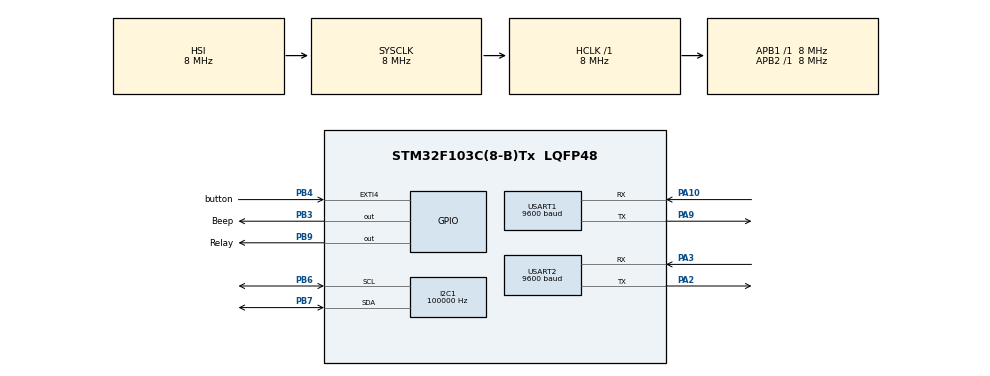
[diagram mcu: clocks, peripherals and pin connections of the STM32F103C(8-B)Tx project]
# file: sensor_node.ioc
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Mcu.Family=STM32F1
NVIC.EXTI4_IRQn=true\:0\:0\:false\:false\:true\:true\:true
PB9.GPIO_Label=Relay
PA10.Mode=Asynchronous
USART1.BaudRate=9600
USART2.BaudRate=9600
ProjectManager.StackSize=0x400
PA13.Signal=SYS_JTMS-SWDIO
PA3.Mode=Asynchronous
PA9.Mode=Asynchronous
I2C1.ClockSpeed=100000
ProjectManager.TargetToolchain=MDK-ARM V5.27
RCC.HCLKFreq_Value=8000000
RCC.APB2TimFreq_Value=8000000
PA9.Signal=USART1_TX
PB6.Signal=I2C1_SCL
PB6.Mode=I2C
RCC.USBFreq_Value=8000000
RCC.AHBFreq_Value=8000000
board=custom
RCC.APB2Freq_Value=8000000
PB4.GPIO_Label=button
PA14.Mode=Serial_Wire
PB7.Signal=I2C1_SDA
PA13.Mode=Serial_Wire
Mcu.Name=STM32F103C(8-B)Tx
PA2.Signal=USART2_TX
PB3.Signal=GPIO_Output
RCC.SYSCLKFreq_VALUE=8000000
Mcu.Package=LQFP48
PB9.Signal=GPIO_Output
USART2.VirtualMode=VM_ASYNC
USART1.VirtualMode=VM_ASYNC
PB7.Mode=I2C
PA10.Signal=USART1_RX
PA14.Signal=SYS_JTCK-SWCLK
ProjectManager.HeapSize=0x200
NVIC.PriorityGroup=NVIC_PRIORITYGROUP_4
RCC.APB1TimFreq_Value=8000000
PA2.Mode=Asynchronous
RCC.APB1Freq_Value=8000000
PB4.Signal=GPXTI4
PA3.Signal=USART2_RX
PB3.GPIO_Label=Beep

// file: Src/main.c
/* USER CODE BEGIN Header */
/**
  ******************************************************************************
  * @file           : main.c
  * @brief          : Main program body
  ******************************************************************************
  * @attention
  *
  * <h2><center>&copy; Copyright (c) 2020 STMicroelectronics.
  * All rights reserved.</center></h2>
  *
  * This software component is licensed by ST under BSD 3-Clause license,
  * the "License"; You may not use this file except in compliance with the
  * License. You may obtain a copy of the License at:
  *                        opensource.org/licenses/BSD-3-Clause
  *
  ******************************************************************************
  */
/* USER CODE END Header */

#include "main.h"
#include "stdio.h"
#include "i2c-lcd.h"

I2C_HandleTypeDef hi2c1;

UART_HandleTypeDef huart1;
UART_HandleTypeDef huart2;

void SystemClock_Config(void);
static void MX_GPIO_Init(void);
static void MX_I2C1_Init(void);
static void MX_USART1_UART_Init(void);
static void MX_USART2_UART_Init(void);
/* USER CODE BEGIN PFP */
int read_MHZ19(void);
void read_HDC(void);
void display(void);
float temp, humi;
unsigned char buffer[5];
unsigned char rawT, rawH;
int co2;

/* USER CODE END PFP */

int main(void)
{

  /* MCU Configuration--------------------------------------------------------*/

  /* Reset of all peripherals, Initializes the Flash interface and the Systick. */
  HAL_Init();

  /* Configure the system clock */
  SystemClock_Config();

  /* Initialize all configured peripherals */
  MX_GPIO_Init();
  MX_I2C1_Init();
  MX_USART1_UART_Init();
  MX_USART2_UART_Init();
buffer[0] = 0x02;
	buffer[1] = 0;
	buffer[2] = 0;
	HAL_I2C_Master_Transmit(&hi2c1, 0x40<<1, buffer, 3, 1000);
	//LCD setup
	lcd_init();
	lcd_goto_XY(1,0);
	lcd_send_string("T:");
	lcd_goto_XY(2,0);
	lcd_send_string("H:");
	lcd_goto_XY(1,7);
	lcd_send_string("CO2:");
	lcd_goto_XY(2,7);
	lcd_send_string("RELAY:");
	lcd_goto_XY(2,13);
	lcd_send_string("OFF");

  /* Infinite loop */
  while (1)
  {
		//display MHZ
		display();
		unsigned char send[4];
		send[0] = 0x42;
		send[1] = co2 >> 8;
		send[2] = co2;
		if(HAL_GPIO_ReadPin(Relay_GPIO_Port, Relay_Pin))	send[3] = 0x01;
		else send[3] = 0x00;
		HAL_UART_Transmit(&huart1, (uint8_t *)send, 4, 1000);
		HAL_Delay(2000);

  }
}
void display(void){
	lcd_goto_XY(1,0);
	lcd_send_string("T:");
	lcd_goto_XY(2,0);
	lcd_send_string("H:");
	lcd_goto_XY(1,7);
	lcd_send_string("CO2:");
	lcd_goto_XY(2,7);
	lcd_send_string("RELAY:");
	co2 = read_MHZ19();
		char tv_co2[4];
		sprintf(tv_co2,"%d",co2);
		lcd_goto_XY(1,12);
		lcd_send_string(tv_co2);
		//display HDC
		read_HDC();
		char tv_temp[5];
		char tv_humi[5];
		sprintf(tv_temp,"%2.f",temp);
		sprintf(tv_humi,"%2.f",humi);
		lcd_goto_XY(1,3);
		lcd_send_string(tv_temp);
		lcd_goto_XY(2,3);
		lcd_send_string(tv_humi);
}

int read_MHZ19(void){
	unsigned char cmd[9] = {0xFF, 0x01, 0x86, 0x00, 0x00, 0x00, 0x00, 0x00, 0x79};
  // command to ask for data
  unsigned char response[9]; // for answer
  HAL_UART_Transmit(&huart2,cmd,9,9600);
	if(HAL_UART_Receive(&huart2,response,9,2000)==HAL_OK){
		if (response[1] != 0x86){
			//Serial.println("Invalid response from co2 sensor!");
			return -1;
		}
		unsigned char crc = 0;
		for (int i = 1; i < 8; i++) {
			crc += response[i];
		}
		crc = 255 - crc + 1;
		if (response[8] == crc) {
			int responseHigh = (int) response[2];
			int responseLow = (int) response[3];
			int ppm = (256 * responseHigh) + responseLow;
			if(ppm <400) ppm = 400;
			else if(ppm>5000) ppm = 5000;
			else ppm = ppm;
			return ppm;
		} else {
			//Serial.println("CRC error!");
			return -1;
		}
	}
}

void read_HDC(void){
	//read temp
	buffer[0] = 0x00;
	HAL_I2C_Master_Transmit(&hi2c1, 0x40<<1, buffer,1,100);
	HAL_Delay(20);
	HAL_I2C_Master_Receive(&hi2c1, 0x40<<1, buffer,2,100);
	rawT = buffer[0] <<8|buffer[1];
	temp = (float)((rawT/65536)*165.0 -40);
	//reaq humi
	buffer[0] = 0x01;
	HAL_I2C_Master_Transmit(&hi2c1, 0x40<<1, buffer,1,1000);
	HAL_Delay(20);
	HAL_I2C_Master_Receive(&hi2c1, 0x40<<1, buffer,2,1000);
	rawH = buffer[0] <<8|buffer[1];
	humi = (float)((rawT/65536)*1000);
	//check data read
	if((temp<-20) || (temp>120)) temp = -1;
	else temp = temp;

	if((humi>99.99) || (humi<0.1)) humi = -1;
	else humi = humi;

}

void SystemClock_Config(void)
{
  RCC_OscInitTypeDef RCC_OscInitStruct = {0};
  RCC_ClkInitTypeDef RCC_ClkInitStruct = {0};

  /** Initializes the CPU, AHB and APB busses clocks
  */
  RCC_OscInitStruct.OscillatorType = RCC_OSCILLATORTYPE_HSI;
  RCC_OscInitStruct.HSIState = RCC_HSI_ON;
  RCC_OscInitStruct.HSICalibrationValue = RCC_HSICALIBRATION_DEFAULT;
  RCC_OscInitStruct.PLL.PLLState = RCC_PLL_NONE;
  if (HAL_RCC_OscConfig(&RCC_OscInitStruct) != HAL_OK)
  {
    Error_Handler();
  }
  /** Initializes the CPU, AHB and APB busses clocks
  */
  RCC_ClkInitStruct.ClockType = RCC_CLOCKTYPE_HCLK|RCC_CLOCKTYPE_SYSCLK
                              |RCC_CLOCKTYPE_PCLK1|RCC_CLOCKTYPE_PCLK2;
  RCC_ClkInitStruct.SYSCLKSource = RCC_SYSCLKSOURCE_HSI;
  RCC_ClkInitStruct.AHBCLKDivider = RCC_SYSCLK_DIV1;
  RCC_ClkInitStruct.APB1CLKDivider = RCC_HCLK_DIV1;
  RCC_ClkInitStruct.APB2CLKDivider = RCC_HCLK_DIV1;

  if (HAL_RCC_ClockConfig(&RCC_ClkInitStruct, FLASH_LATENCY_0) != HAL_OK)
  {
    Error_Handler();
  }
}

static void MX_I2C1_Init(void)
{

  hi2c1.Instance = I2C1;
  hi2c1.Init.ClockSpeed = 100000;
  hi2c1.Init.DutyCycle = I2C_DUTYCYCLE_2;
  hi2c1.Init.OwnAddress1 = 0;
  hi2c1.Init.AddressingMode = I2C_ADDRESSINGMODE_7BIT;
  hi2c1.Init.DualAddressMode = I2C_DUALADDRESS_DISABLE;
  hi2c1.Init.OwnAddress2 = 0;
  hi2c1.Init.GeneralCallMode = I2C_GENERALCALL_DISABLE;
  hi2c1.Init.NoStretchMode = I2C_NOSTRETCH_DISABLE;
  if (HAL_I2C_Init(&hi2c1) != HAL_OK)
  {
    Error_Handler();
  }

}

static void MX_USART1_UART_Init(void)
{

  huart1.Instance = USART1;
  huart1.Init.BaudRate = 9600;
  huart1.Init.WordLength = UART_WORDLENGTH_8B;
  huart1.Init.StopBits = UART_STOPBITS_1;
  huart1.Init.Parity = UART_PARITY_NONE;
  huart1.Init.Mode = UART_MODE_TX_RX;
  huart1.Init.HwFlowCtl = UART_HWCONTROL_NONE;
  huart1.Init.OverSampling = UART_OVERSAMPLING_16;
  if (HAL_UART_Init(&huart1) != HAL_OK)
  {
    Error_Handler();
  }

}

static void MX_USART2_UART_Init(void)
{

  huart2.Instance = USART2;
  huart2.Init.BaudRate = 9600;
  huart2.Init.WordLength = UART_WORDLENGTH_8B;
  huart2.Init.StopBits = UART_STOPBITS_1;
  huart2.Init.Parity = UART_PARITY_NONE;
  huart2.Init.Mode = UART_MODE_TX_RX;
  huart2.Init.HwFlowCtl = UART_HWCONTROL_NONE;
  huart2.Init.OverSampling = UART_OVERSAMPLING_16;
  if (HAL_UART_Init(&huart2) != HAL_OK)
  {
    Error_Handler();
  }

}

static void MX_GPIO_Init(void)
{
  GPIO_InitTypeDef GPIO_InitStruct = {0};

  /* GPIO Ports Clock Enable */
  __HAL_RCC_GPIOA_CLK_ENABLE();
  __HAL_RCC_GPIOB_CLK_ENABLE();

  /*Configure GPIO pin Output Level */
  HAL_GPIO_WritePin(GPIOB, Beep_Pin|Relay_Pin, GPIO_PIN_RESET);

  /*Configure GPIO pins : Beep_Pin Relay_Pin */
  GPIO_InitStruct.Pin = Beep_Pin|Relay_Pin;
  GPIO_InitStruct.Mode = GPIO_MODE_OUTPUT_PP;
  GPIO_InitStruct.Pull = GPIO_NOPULL;
  GPIO_InitStruct.Speed = GPIO_SPEED_FREQ_LOW;
  HAL_GPIO_Init(GPIOB, &GPIO_InitStruct);

  /*Configure GPIO pin : button_Pin */
  GPIO_InitStruct.Pin = button_Pin;
  GPIO_InitStruct.Mode = GPIO_MODE_IT_RISING;
  GPIO_InitStruct.Pull = GPIO_PULLUP;
  HAL_GPIO_Init(button_GPIO_Port, &GPIO_InitStruct);

  /* EXTI interrupt init*/
  HAL_NVIC_SetPriority(EXTI4_IRQn, 0, 0);
  HAL_NVIC_EnableIRQ(EXTI4_IRQn);

}

void Error_Handler(void)
{
}

/************************ (C) COPYRIGHT STMicroelectronics *****END OF FILE****/
